# nrf54ls05a_application register map
Vendor: Nordic Semiconductor; Series: nrf54l; File version: 1
CPU: CM33 r0p4, little endian, no MPU, no FPU, 3 interrupt priority bits, 270 interrupts
Registers are 32-bit, read-write, reset 0x0 unless marked. A register's access mark holds for its fields unless they carry their own. Offsets are from the block's base; [hi:lo] are bit positions; lines under a group give offsets from that group; {n}, {i} and the like mark numbered series; 'fields as' and 'values as' point back to an identical list.

## GLOBAL_RADIO — 2.4 GHz radio
Base 0x4008A000
0x00 TASKS_TXEN wo — Enable RADIO in TX mode
  [0] TASKS_TXEN
    1=Trigger task
0x04 TASKS_RXEN wo — Enable RADIO in RX mode
  [0] TASKS_RXEN
    1=Trigger task
0x08 TASKS_START wo — Start RADIO
  [0] TASKS_START
    1=Trigger task
0x0C TASKS_STOP wo — Stop RADIO
  [0] TASKS_STOP
    1=Trigger task
0x10 TASKS_DISABLE wo — Disable RADIO
  [0] TASKS_DISABLE
    1=Trigger task
0x14 TASKS_RSSISTART wo — Start the RSSI and take one single sample of the receive signal strength
  [0] TASKS_RSSISTART
    1=Trigger task
0x18 TASKS_BCSTART wo — Start the bit counter
  [0] TASKS_BCSTART
    1=Trigger task
0x1C TASKS_BCSTOP wo — Stop the bit counter
  [0] TASKS_BCSTOP
    1=Trigger task
0x6C TASKS_PLLEN wo — Enable RADIO in PLL mode (standby for either TX or RX)
  [0] TASKS_PLLEN
    1=Trigger task
0xA4 TASKS_SOFTRESET wo — Reset all public registers, but with these exceptions: DMA registers and EVENT/INTEN/SUBSCRIBE/PUBLISH registers. Only to be used in DISABLED state.
  [0] TASKS_SOFTRESET
    1=Trigger task
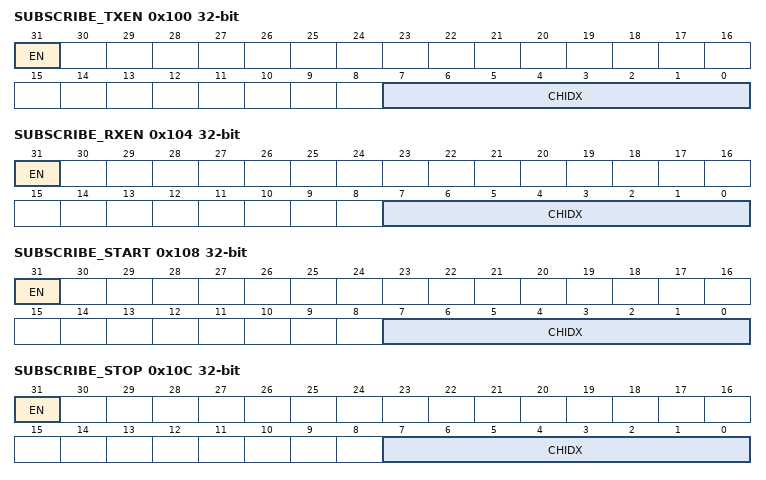
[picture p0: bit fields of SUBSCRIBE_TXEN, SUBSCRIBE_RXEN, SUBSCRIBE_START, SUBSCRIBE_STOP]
0x100 SUBSCRIBE_TXEN — Subscribe configuration for task TXEN
  [31] EN
    0=Disabled (Disable subscription); 1=Enabled (Enable subscription)
  [7:0] CHIDX — DPPI channel that task TXEN will subscribe to
0x104 SUBSCRIBE_RXEN — Subscribe configuration for task RXEN
  [31] EN
    values as SUBSCRIBE_TXEN.EN
  [7:0] CHIDX — DPPI channel that task RXEN will subscribe to
0x108 SUBSCRIBE_START — Subscribe configuration for task START
  [31] EN
    values as SUBSCRIBE_TXEN.EN
  [7:0] CHIDX — DPPI channel that task START will subscribe to
0x10C SUBSCRIBE_STOP — Subscribe configuration for task STOP
  [31] EN
    values as SUBSCRIBE_TXEN.EN
  [7:0] CHIDX — DPPI channel that task STOP will subscribe to
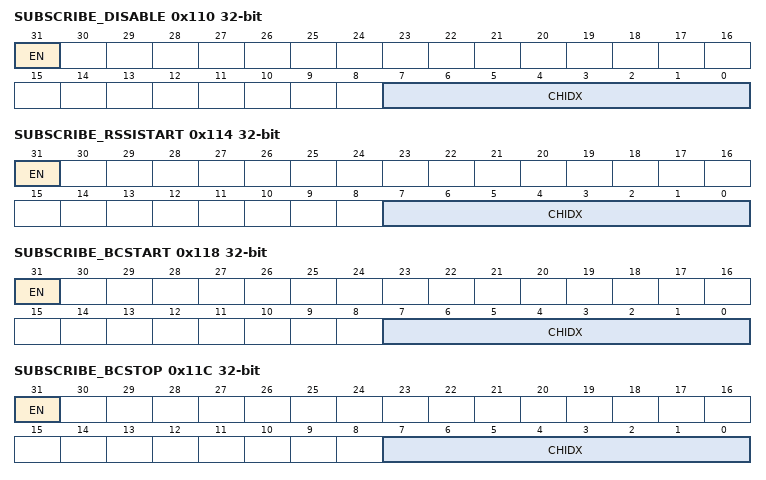
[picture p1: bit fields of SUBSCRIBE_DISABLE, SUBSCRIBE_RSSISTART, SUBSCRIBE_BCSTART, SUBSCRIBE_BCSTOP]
0x110 SUBSCRIBE_DISABLE — Subscribe configuration for task DISABLE
  [31] EN
    values as SUBSCRIBE_TXEN.EN
  [7:0] CHIDX — DPPI channel that task DISABLE will subscribe to
0x114 SUBSCRIBE_RSSISTART — Subscribe configuration for task RSSISTART
  [31] EN
    values as SUBSCRIBE_TXEN.EN
  [7:0] CHIDX — DPPI channel that task RSSISTART will subscribe to
0x118 SUBSCRIBE_BCSTART — Subscribe configuration for task BCSTART
  [31] EN
    values as SUBSCRIBE_TXEN.EN
  [7:0] CHIDX — DPPI channel that task BCSTART will subscribe to
0x11C SUBSCRIBE_BCSTOP — Subscribe configuration for task BCSTOP
  [31] EN
    values as SUBSCRIBE_TXEN.EN
  [7:0] CHIDX — DPPI channel that task BCSTOP will subscribe to
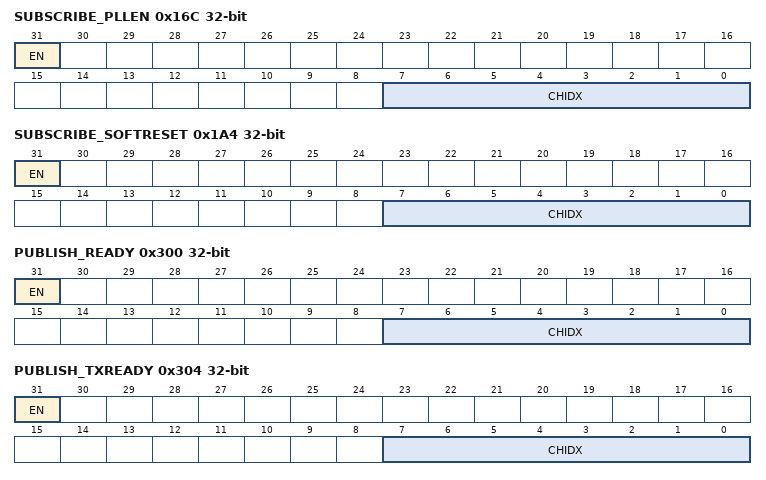
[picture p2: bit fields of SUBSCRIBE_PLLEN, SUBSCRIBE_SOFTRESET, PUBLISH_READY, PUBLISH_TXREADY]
0x16C SUBSCRIBE_PLLEN — Subscribe configuration for task PLLEN
  [31] EN
    values as SUBSCRIBE_TXEN.EN
  [7:0] CHIDX — DPPI channel that task PLLEN will subscribe to
0x1A4 SUBSCRIBE_SOFTRESET — Subscribe configuration for task SOFTRESET
  [31] EN
    values as SUBSCRIBE_TXEN.EN
  [7:0] CHIDX — DPPI channel that task SOFTRESET will subscribe to
0x200 EVENTS_READY — RADIO has ramped up and is ready to be started
  [0] EVENTS_READY
    0=NotGenerated (Event not generated); 1=Generated (Event generated)
0x204 EVENTS_TXREADY — RADIO has ramped up and is ready to be started TX path
  [0] EVENTS_TXREADY
    values as EVENTS_READY.EVENTS_READY
0x208 EVENTS_RXREADY — RADIO has ramped up and is ready to be started RX path
  [0] EVENTS_RXREADY
    values as EVENTS_READY.EVENTS_READY
0x20C EVENTS_ADDRESS — Address sent or received
  [0] EVENTS_ADDRESS
    values as EVENTS_READY.EVENTS_READY
0x214 EVENTS_PAYLOAD — Packet payload sent or received
  [0] EVENTS_PAYLOAD
    values as EVENTS_READY.EVENTS_READY
0x218 EVENTS_END — Memory access for packet data has been completed
  [0] EVENTS_END
    values as EVENTS_READY.EVENTS_READY
0x21C EVENTS_PHYEND — The last bit is sent on air or last bit is received
  [0] EVENTS_PHYEND
    values as EVENTS_READY.EVENTS_READY
0x220 EVENTS_DISABLED — RADIO has been disabled
  [0] EVENTS_DISABLED
    values as EVENTS_READY.EVENTS_READY
0x224 EVENTS_DEVMATCH — A device address match occurred on the last received packet
  [0] EVENTS_DEVMATCH
    values as EVENTS_READY.EVENTS_READY
0x228 EVENTS_DEVMISS — No device address match occurred on the last received packet
  [0] EVENTS_DEVMISS
    values as EVENTS_READY.EVENTS_READY
0x22C EVENTS_CRCOK — Packet received with CRC ok
  [0] EVENTS_CRCOK
    values as EVENTS_READY.EVENTS_READY
0x230 EVENTS_CRCERROR — Packet received with CRC error
  [0] EVENTS_CRCERROR
    values as EVENTS_READY.EVENTS_READY
0x238 EVENTS_BCMATCH — Bit counter reached bit count value
  [0] EVENTS_BCMATCH
    values as EVENTS_READY.EVENTS_READY
0x258 EVENTS_SYNC — Initial sync detected
  [0] EVENTS_SYNC
    values as EVENTS_READY.EVENTS_READY
0x2B0 EVENTS_PLLREADY — PLL has settled and RADIO is ready to be enabled in either TX or RX mode
  [0] EVENTS_PLLREADY
    values as EVENTS_READY.EVENTS_READY
0x2BC EVENTS_RXADDRESS — Address received
  [0] EVENTS_RXADDRESS
    values as EVENTS_READY.EVENTS_READY
0x300 PUBLISH_READY — Publish configuration for event READY
  [31] EN
    0=Disabled (Disable publishing); 1=Enabled (Enable publishing)
  [7:0] CHIDX — DPPI channel that event READY will publish to
0x304 PUBLISH_TXREADY — Publish configuration for event TXREADY
  [31] EN
    values as PUBLISH_READY.EN
  [7:0] CHIDX — DPPI channel that event TXREADY will publish to
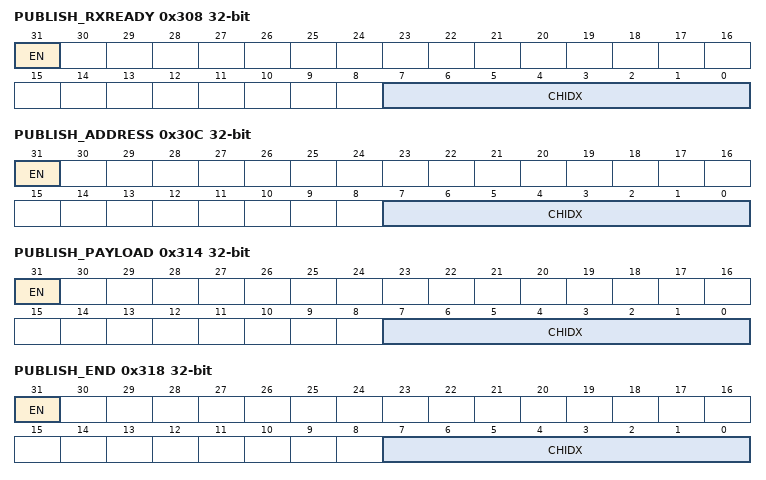
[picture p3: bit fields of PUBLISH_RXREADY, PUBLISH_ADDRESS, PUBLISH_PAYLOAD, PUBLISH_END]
0x308 PUBLISH_RXREADY — Publish configuration for event RXREADY
  [31] EN
    values as PUBLISH_READY.EN
  [7:0] CHIDX — DPPI channel that event RXREADY will publish to
0x30C PUBLISH_ADDRESS — Publish configuration for event ADDRESS
  [31] EN
    values as PUBLISH_READY.EN
  [7:0] CHIDX — DPPI channel that event ADDRESS will publish to
0x314 PUBLISH_PAYLOAD — Publish configuration for event PAYLOAD
  [31] EN
    values as PUBLISH_READY.EN
  [7:0] CHIDX — DPPI channel that event PAYLOAD will publish to
0x318 PUBLISH_END — Publish configuration for event END
  [31] EN
    values as PUBLISH_READY.EN
  [7:0] CHIDX — DPPI channel that event END will publish to
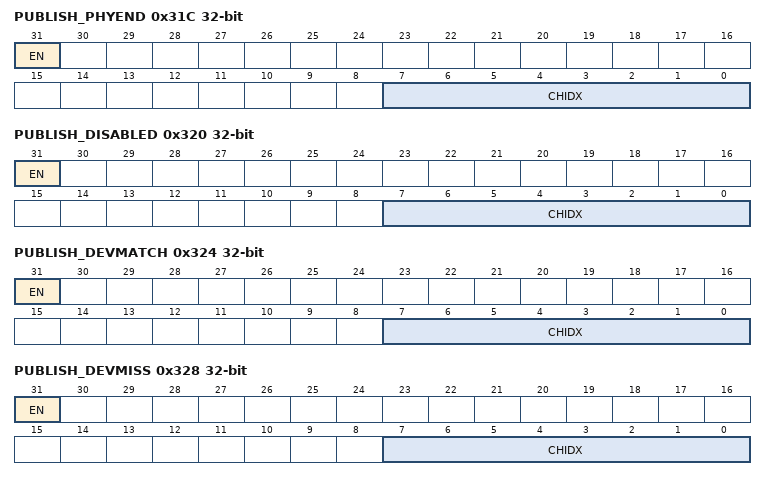
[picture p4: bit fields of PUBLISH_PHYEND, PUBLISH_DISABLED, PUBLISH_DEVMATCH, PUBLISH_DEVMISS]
0x31C PUBLISH_PHYEND — Publish configuration for event PHYEND
  [31] EN
    values as PUBLISH_READY.EN
  [7:0] CHIDX — DPPI channel that event PHYEND will publish to
0x320 PUBLISH_DISABLED — Publish configuration for event DISABLED
  [31] EN
    values as PUBLISH_READY.EN
  [7:0] CHIDX — DPPI channel that event DISABLED will publish to
0x324 PUBLISH_DEVMATCH — Publish configuration for event DEVMATCH
  [31] EN
    values as PUBLISH_READY.EN
  [7:0] CHIDX — DPPI channel that event DEVMATCH will publish to
0x328 PUBLISH_DEVMISS — Publish configuration for event DEVMISS
  [31] EN
    values as PUBLISH_READY.EN
  [7:0] CHIDX — DPPI channel that event DEVMISS will publish to
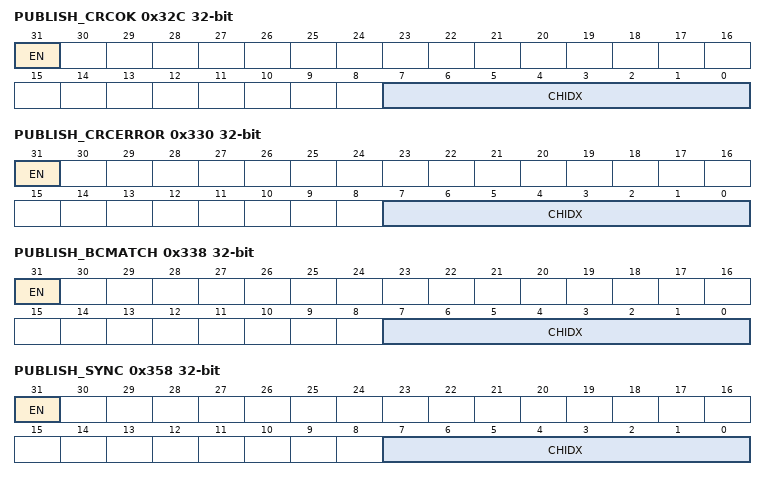
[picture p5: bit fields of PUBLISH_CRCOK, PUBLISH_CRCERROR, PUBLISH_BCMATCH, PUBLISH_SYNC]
0x32C PUBLISH_CRCOK — Publish configuration for event CRCOK
  [31] EN
    values as PUBLISH_READY.EN
  [7:0] CHIDX — DPPI channel that event CRCOK will publish to
0x330 PUBLISH_CRCERROR — Publish configuration for event CRCERROR
  [31] EN
    values as PUBLISH_READY.EN
  [7:0] CHIDX — DPPI channel that event CRCERROR will publish to
0x338 PUBLISH_BCMATCH — Publish configuration for event BCMATCH
  [31] EN
    values as PUBLISH_READY.EN
  [7:0] CHIDX — DPPI channel that event BCMATCH will publish to
0x358 PUBLISH_SYNC — Publish configuration for event SYNC
  [31] EN
    values as PUBLISH_READY.EN
  [7:0] CHIDX — DPPI channel that event SYNC will publish to
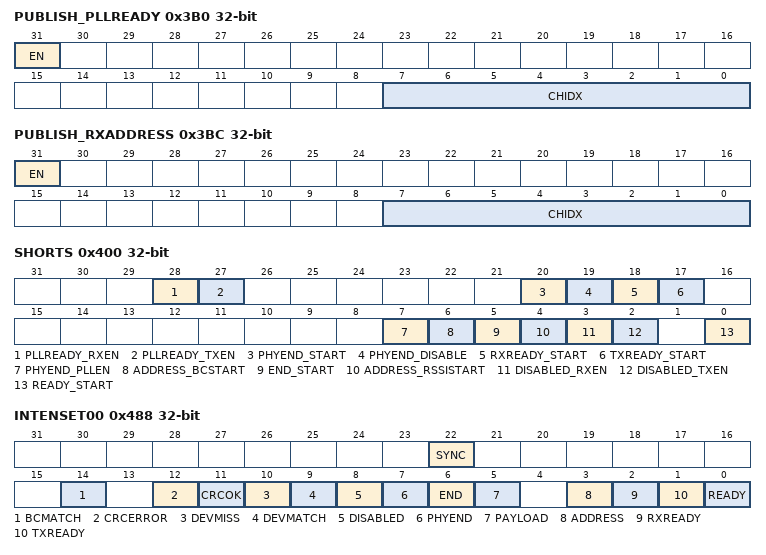
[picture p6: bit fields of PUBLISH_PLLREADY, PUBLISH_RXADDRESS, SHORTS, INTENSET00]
0x3B0 PUBLISH_PLLREADY — Publish configuration for event PLLREADY
  [31] EN
    values as PUBLISH_READY.EN
  [7:0] CHIDX — DPPI channel that event PLLREADY will publish to
0x3BC PUBLISH_RXADDRESS — Publish configuration for event RXADDRESS
  [31] EN
    values as PUBLISH_READY.EN
  [7:0] CHIDX — DPPI channel that event RXADDRESS will publish to
0x400 SHORTS — Shortcuts between local events and tasks
  [all] fields
    0=Disabled (Disable shortcut); 1=Enabled (Enable shortcut)
  [28] PLLREADY_RXEN — Shortcut between event PLLREADY and task RXEN
  [27] PLLREADY_TXEN — Shortcut between event PLLREADY and task TXEN
  [20] PHYEND_START — Shortcut between event PHYEND and task START
  [19] PHYEND_DISABLE — Shortcut between event PHYEND and task DISABLE
  [18] RXREADY_START — Shortcut between event RXREADY and task START
  [17] TXREADY_START — Shortcut between event TXREADY and task START
  [7] PHYEND_PLLEN — Shortcut between event PHYEND and task PLLEN
  [6] ADDRESS_BCSTART — Shortcut between event ADDRESS and task BCSTART
  [5] END_START — Shortcut between event END and task START
  [4] ADDRESS_RSSISTART — Shortcut between event ADDRESS and task RSSISTART
  [3] DISABLED_RXEN — Shortcut between event DISABLED and task RXEN
  [2] DISABLED_TXEN — Shortcut between event DISABLED and task TXEN
  [0] READY_START — Shortcut between event READY and task START
0x488 INTENSET00 — Enable interrupt
  [all] fields
    on read: 0=Disabled (Read: Disabled); 1=Enabled (Read: Enabled) | on write: 1=Set (Enable)
  [22] SYNC write-1-sets — Write '1' to enable interrupt for event SYNC
  [14] BCMATCH write-1-sets — Write '1' to enable interrupt for event BCMATCH
  [12] CRCERROR write-1-sets — Write '1' to enable interrupt for event CRCERROR
  [11] CRCOK write-1-sets — Write '1' to enable interrupt for event CRCOK
  [10] DEVMISS write-1-sets — Write '1' to enable interrupt for event DEVMISS
  [9] DEVMATCH write-1-sets — Write '1' to enable interrupt for event DEVMATCH
  [8] DISABLED write-1-sets — Write '1' to enable interrupt for event DISABLED
  [7] PHYEND write-1-sets — Write '1' to enable interrupt for event PHYEND
  [6] END write-1-sets — Write '1' to enable interrupt for event END
  [5] PAYLOAD write-1-sets — Write '1' to enable interrupt for event PAYLOAD
  [3] ADDRESS write-1-sets — Write '1' to enable interrupt for event ADDRESS
  [2] RXREADY write-1-sets — Write '1' to enable interrupt for event RXREADY
  [1] TXREADY write-1-sets — Write '1' to enable interrupt for event TXREADY
  [0] READY write-1-sets — Write '1' to enable interrupt for event READY
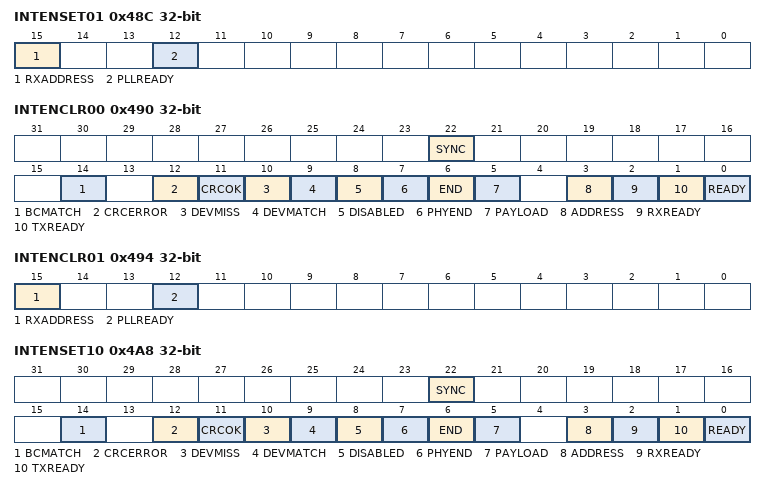
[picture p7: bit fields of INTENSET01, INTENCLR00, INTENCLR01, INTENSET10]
0x48C INTENSET01 — Enable interrupt
  [15] RXADDRESS write-1-sets — Write '1' to enable interrupt for event RXADDRESS
    values as the fields of INTENSET00
  [12] PLLREADY write-1-sets — Write '1' to enable interrupt for event PLLREADY
    values as the fields of INTENSET00
0x490 INTENCLR00 — Disable interrupt
  [all] fields
    on read: 0=Disabled (Read: Disabled); 1=Enabled (Read: Enabled) | on write: 1=Clear (Disable)
  [22] SYNC write-1-clears — Write '1' to disable interrupt for event SYNC
  [14] BCMATCH write-1-clears — Write '1' to disable interrupt for event BCMATCH
  [12] CRCERROR write-1-clears — Write '1' to disable interrupt for event CRCERROR
  [11] CRCOK write-1-clears — Write '1' to disable interrupt for event CRCOK
  [10] DEVMISS write-1-clears — Write '1' to disable interrupt for event DEVMISS
  [9] DEVMATCH write-1-clears — Write '1' to disable interrupt for event DEVMATCH
  [8] DISABLED write-1-clears — Write '1' to disable interrupt for event DISABLED
  [7] PHYEND write-1-clears — Write '1' to disable interrupt for event PHYEND
  [6] END write-1-clears — Write '1' to disable interrupt for event END
  [5] PAYLOAD write-1-clears — Write '1' to disable interrupt for event PAYLOAD
  [3] ADDRESS write-1-clears — Write '1' to disable interrupt for event ADDRESS
  [2] RXREADY write-1-clears — Write '1' to disable interrupt for event RXREADY
  [1] TXREADY write-1-clears — Write '1' to disable interrupt for event TXREADY
  [0] READY write-1-clears — Write '1' to disable interrupt for event READY
0x494 INTENCLR01 — Disable interrupt
  [15] RXADDRESS write-1-clears — Write '1' to disable interrupt for event RXADDRESS
    values as the fields of INTENCLR00
  [12] PLLREADY write-1-clears — Write '1' to disable interrupt for event PLLREADY
    values as the fields of INTENCLR00
0x4A8 INTENSET10 — Enable interrupt
  fields as INTENSET00
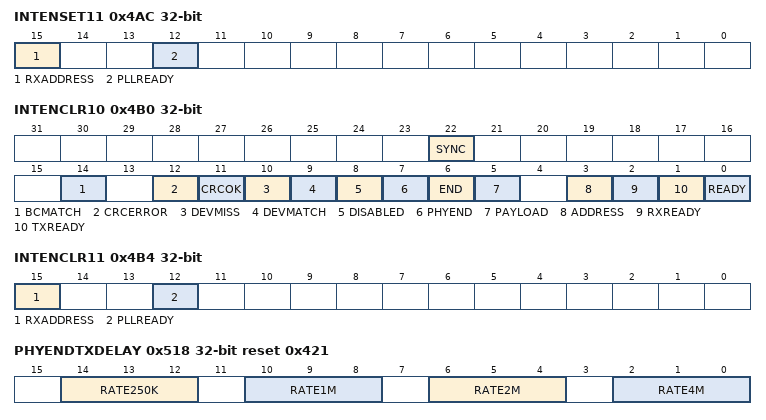
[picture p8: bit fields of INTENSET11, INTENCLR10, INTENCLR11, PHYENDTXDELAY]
0x4AC INTENSET11 — Enable interrupt
  fields as INTENSET01
0x4B0 INTENCLR10 — Disable interrupt
  fields as INTENCLR00
0x4B4 INTENCLR11 — Disable interrupt
  fields as INTENCLR01
0x500 MODE — Data rate and modulation
  [3:0] MODE — Radio data rate and modulation setting. The radio supports frequency-shift keying (FSK) modulation.
    0=Nrf_1Mbit (1 Mbps Nordic proprietary radio mode); 1=Nrf_2Mbit (2 Mbps Nordic proprietary radio mode); 3=Ble_1Mbit (1 Mbps BLE); 4=Ble_2Mbit (2 Mbps BLE); 9=Nrf_4Mbit_0BT6 (4 Mbps Nordic proprietary radio mode (BT=0.6/h=0.5)); 10=Nrf_4Mbit_0BT4 (4 Mbps Nordic proprietary radio mode (BT=0.4/h=0.5))
0x518 PHYENDTXDELAY reset 0x421 — Configurable delay of PHYEND event for TX
  [14:12] RATE250K — For modes with 250 kbps on-air bit rate, unit is 1/8 bit period (Nrf_250Kbit mode)
  [10:8] RATE1M — For modes with 1 Mbps on-air bit rate, unit is 1/2 bit period (Nrf_1Mbit and Ble_1Mbit modes)
  [6:4] RATE2M — For modes with 2 Mbps on-air bit rate, unit is 1 bit period (Nrf_2Mbit, Ble_2Mbit, and Ieee802154_250Kbit modes)
  [2:0] RATE4M — For modes with 4 Mbps on-air bit rate, unit is 2 bit periods (Nrf_4Mbit0_5 and Nrf_4Mbit0_25 modes)
0x520 STATE ro — Current radio state
  [3:0] STATE
    0=Disabled (RADIO is in the DISABLED state); 1=RxRu (RADIO is in the RXRU state); 2=RxIdle (RADIO is in the RXIDLE state); 3=Rx (RADIO is in the RX state); 4=RxDisable (RADIO is in the RXDISABLE state); 5=Settle (RADIO is in the SETTLE state); 6=Pll (RADIO is in the PLL state); 9=TxRu (RADIO is in the TXRU state); 10=TxIdle (RADIO is in the TXIDLE state); 11=Tx (RADIO is in the TX state); 12=TxDisable (RADIO is in the TXDISABLE state)
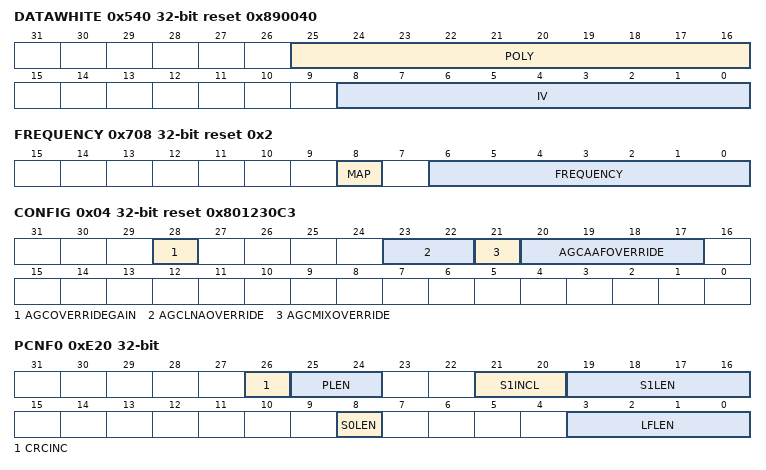
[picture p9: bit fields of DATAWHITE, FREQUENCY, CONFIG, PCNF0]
0x540 DATAWHITE reset 0x890040 — Data whitening configuration
  [25:16] POLY — Whitening polynomial
  [8:0] IV — Whitening initial value
0x704 TIMING reset 0x1
  [0] RU — Ramp-up time
    0=Legacy ramp-up time; 1=Fast ramp-up (default)
0x708 FREQUENCY reset 0x2
  [8] MAP — Channel map selection. 0: Channel map between 2400 MHZ to 2500 MHz, Frequency = 2400 + FREQUENCY (MHz). 1: Channel map between 2360 MHZ to 2460 MHz, Frequency = 2360 + FREQUENCY (MHz).
  [6:0] FREQUENCY — Radio channel frequency. Frequency = 2400 + FREQUENCY (MHz).
0x710 TXPOWER reset 0x13 — Output power
  [10:0] TXPOWER — RADIO output power
    63=MaxdBm (+8 dBm); 63=Pos8dBm (+8 dBm); 57=Pos7dBm (+7 dBm); 51=Pos6dBm (+6 dBm); 45=Pos5dBm (+5 dBm); 40=Pos4dBm (+4 dBm); 35=Pos3dBm (+3 dBm); 31=Pos2dBm (+2 dBm); 27=Pos1dBm (+1 dBm); 24=0dBm; 21=Neg1dBm (-1 dBm); 19=Neg2dBm (-2 dBm); 17=Neg3dBm (-3 dBm); 15=Neg4dBm (-4 dBm); 13=Neg5dBm (-5 dBm); 11=Neg6dBm (-6 dBm); 10=Neg7dBm (-7 dBm); 9=Neg8dBm (-8 dBm); 8=Neg9dBm (-9 dBm); 7=Neg10dBm (-10 dBm); 6=Neg12dBm (-12 dBm); 5=Neg14dBm (-14 dBm); 4=Neg16dBm (-16 dBm); 3=Neg18dBm (-18 dBm); 2=Neg20dBm (-20 dBm); 2=Neg22dBm (-22 dBm); 1=Neg28dBm (-28 dBm); 0x130=Neg40dBm (-40 dBm); 0x110=Neg46dBm (-46 dBm); 0=MindBm (Minimum output power)
0x714 TIFS — Interframe spacing in us
  [9:0] TIFS — Interframe spacing in us. Interframe space is the time interval between two consecutive packets. It is defined as the time, in microseconds, from the end of the last bit of the previous packet to the start of the first bit of the subsequent packet.
0x718 RSSISAMPLE ro reset 0x7F
  [6:0] RSSISAMPLE — RSSI sample result. The value of this register is read as a positive value while the actual received signal strength is a negative value. Actual received signal strength is therefore as follows: received signal strength = -A dBm.
0x7D0 RXGAIN group — Unspecified
  0x04 CONFIG reset 0x801230C3 — Override configuration of receiver gain control loop
    [28] AGCOVERRIDEGAIN — Enable AGC override
      0=NoOverride (AGC takes control over all gains); 1=Override (Manual control of AAF, MIX, and LNA gain settings)
    [23:22] AGCLNAOVERRIDE — Override value for LNA
    [21] AGCMIXOVERRIDE — Override value for MIX
    [20:17] AGCAAFOVERRIDE — Override value for AAF
0x804 FREQFINETUNE — Fine tuning of the RF frequency
  [12:0] FREQFINETUNE — Twos-complement number for fine-tuning the frequency. The step size is 488.28125 Hz, giving a range from -1 MHz to (one step short of) +1 MHz.
0x908 FECONFIG reset 0x10800005 — Config register
  [20] SCALERMODE — Mode for narrow scaling output.
    0=Disabled (Classic log based scaling mode.); 1=Enabled (LUT based scaling mode.)
0xB00 CFO_STAT ro — Carrier freq. offset estimate
  [12] SYNCOK
    0=SyncNotOK (Unspecified); 1=SyncOk (Unspecified)
0xB40 DBCCORR reset 0x1FFFFF90 — Correlator thresholds
  [7:0] TH — Correlation threshold
0xE0C CRCSTATUS ro
  [0] CRCSTATUS — CRC status of packet received
    0=CRCError (Packet received with CRC error); 1=CRCOk (Packet received with CRC ok)
0xE10 RXMATCH ro — Received address
  [2:0] RXMATCH
0xE14 RXCRC ro — CRC field of previously received packet
  [23:0] RXCRC
0xE18 DAI ro — Device address match index
  [2:0] DAI
0xE1C PDUSTAT ro — Payload status
  [0] PDUSTAT — Status on payload length vs. PCNF1.MAXLEN
    0=LessThan (Payload less than PCNF1.MAXLEN); 1=GreaterThan (Payload greater than PCNF1.MAXLEN)
0xE20 PCNF0 — Packet configuration register 0
  [26] CRCINC — Indicates if LENGTH field contains CRC or not
    0=Exclude (LENGTH does not contain CRC); 1=Include (LENGTH includes CRC)
  [25:24] PLEN — Length of preamble on air. Decision point: TASKS_START task
    0=8-bit preamble; 1=16-bit preamble
  [21:20] S1INCL — Include or exclude S1 field in RAM
    0=Automatic (Include S1 field in RAM only if S1LEN > 0); 1=Include (Always include S1 field in RAM independent of S1LEN)
  [19:16] S1LEN — Length on air of S1 field in number of bits.
  [8] S0LEN — Length on air of S0 field in number of bytes.
  [3:0] LFLEN — Length on air of LENGTH field in number of bits.
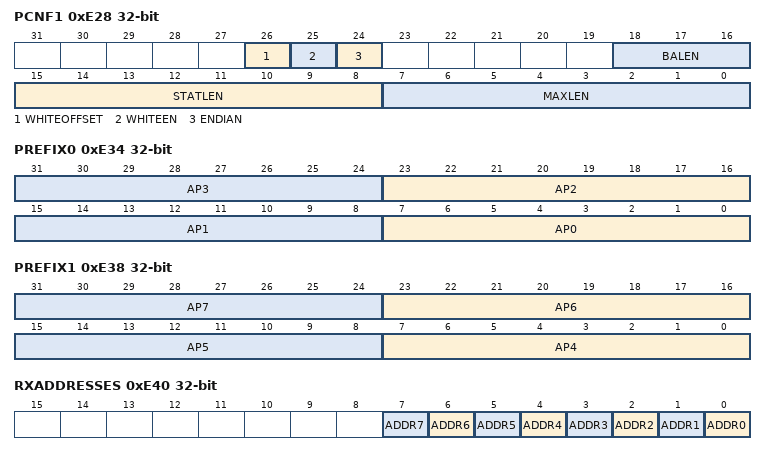
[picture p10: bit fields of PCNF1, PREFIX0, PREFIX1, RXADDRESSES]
0xE28 PCNF1 — Packet configuration register 1
  [26] WHITEOFFSET — If whitening is enabled S0 can be configured to be excluded from whitening
    0=Include (S0 included in whitening); 1=Exclude (S0 excluded from whitening)
  [25] WHITEEN — Enable or disable packet whitening
    0=Disabled; 1=Enabled
  [24] ENDIAN — On-air endianness of packet, this applies to the S0, LENGTH, S1, and the PAYLOAD fields.
    0=Little (Least significant bit on air first); 1=Big (Most significant bit on air first)
  [18:16] BALEN — Base address length in number of bytes
  [15:8] STATLEN — Static length in number of bytes
  [7:0] MAXLEN — Maximum length of packet payload. If the packet payload is larger than MAXLEN, the radio will truncate the payload to MAXLEN.
0xE2C BASE0 — Base address 0
0xE30 BASE1 — Base address 1
0xE34 PREFIX0 — Prefixes bytes for logical addresses 0-3
  [8n+7:8n] AP{n} (n=0..3) — Address prefix {n}
0xE38 PREFIX1 — Prefixes bytes for logical addresses 4-7
  [8n-25:8n-32] AP{n} (n=4..7) — Address prefix {n}
0xE3C TXADDRESS — Transmit address select
  [2:0] TXADDRESS
0xE40 RXADDRESSES — Receive address select
  [all] fields
    0=Disabled; 1=Enabled
  [n] ADDR{n} (n=0..7) — Enable or disable reception on logical address {n}
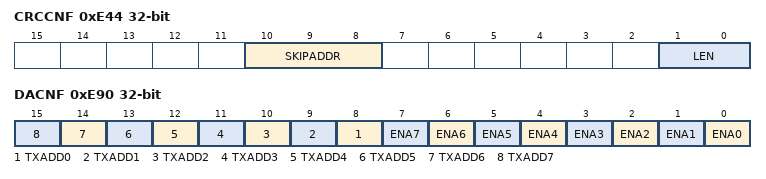
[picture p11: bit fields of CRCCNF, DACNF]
0xE44 CRCCNF — CRC configuration
  [10:8] SKIPADDR — Control whether CRC calculation skips the address field. Other fields can also be skipped.
    0=Include (CRC calculation includes address field); 1=Skip (CRC calculation starting at first byte after address field.); 2=Ieee802154 (CRC calculation starting at first byte after length field (as per 802.15.4 standard).); 3=SkipS0 (CRC calculation starting at first byte after S0 field.); 4=SkipS1 (CRC calculation starting at first byte after S1 field.)
  [1:0] LEN — CRC length in number of bytes.
    0=Disabled (CRC length is zero and CRC calculation is disabled); 1=One (CRC length is one byte and CRC calculation is enabled); 2=Two (CRC length is two bytes and CRC calculation is enabled); 3=Three (CRC length is three bytes and CRC calculation is enabled)
0xE48 CRCPOLY — CRC polynomial
  [23:0] CRCPOLY
0xE4C CRCINIT — CRC initial value
  [23:0] CRCINIT
{0xE50+4i} DAB[{i}] (i=0..7) — Description collection: Device address base segment n
  [31:0] DAB — Device address base segment n
{0xE70+4i} DAP[{i}] (i=0..7) — Description collection: Device address prefix n
  [15:0] DAP — Device address prefix n
0xE90 DACNF — Device address match configuration
  [n+8] TXADD{n} (n=0..7) — TxAdd for device address {n}
  [n] ENA{n} (n=0..7) — Enable or disable device address matching using device address {n}
    0=Disabled; 1=Enabled
0xE94 BCC — Bit counter compare
0xEB4 MHRMATCHCONF — Search pattern configuration
0xEB8 MHRMATCHMASK — Pattern mask
0xED0 PACKETPTR — Packet pointer
  [31:0] PTR — Data pointer

## Notices in the file
Copyright (c) 2010 - 2026, Nordic Semiconductor ASA All rights reserved.
SPDX-License-Identifier: BSD-3-Clause
Redistribution and use in source and binary forms, with or without
modification, are permitted provided that the following conditions are met:
1. Redistributions of source code must retain the above copyright notice, this
list of conditions and the following disclaimer.
2. Redistributions in binary form must reproduce the above copyright
notice, this list of conditions and the following disclaimer in the
documentation and/or other materials provided with the distribution.
3. Neither the name of Nordic Semiconductor ASA nor the names of its
contributors may be used to endorse or promote products derived from this
software without specific prior written permission.
THIS SOFTWARE IS PROVIDED BY THE COPYRIGHT HOLDERS AND CONTRIBUTORS "AS IS"
AND ANY EXPRESS OR IMPLIED WARRANTIES, INCLUDING, BUT NOT LIMITED TO, THE
IMPLIED WARRANTIES OF MERCHANTABILITY, AND FITNESS FOR A PARTICULAR PURPOSE
ARE DISCLAIMED. IN NO EVENT SHALL NORDIC SEMICONDUCTOR ASA OR CONTRIBUTORS BE
LIABLE FOR ANY DIRECT, INDIRECT, INCIDENTAL, SPECIAL, EXEMPLARY, OR
CONSEQUENTIAL DAMAGES (INCLUDING, BUT NOT LIMITED TO, PROCUREMENT OF
SUBSTITUTE GOODS OR SERVICES; LOSS OF USE, DATA, OR PROFITS; OR BUSINESS
INTERRUPTION) HOWEVER CAUSED AND ON ANY THEORY OF LIABILITY, WHETHER IN
CONTRACT, STRICT LIABILITY, OR TORT (INCLUDING NEGLIGENCE OR OTHERWISE)
ARISING IN ANY WAY OUT OF THE USE OF THIS SOFTWARE, EVEN IF ADVISED OF THE
POSSIBILITY OF SUCH DAMAGE.
